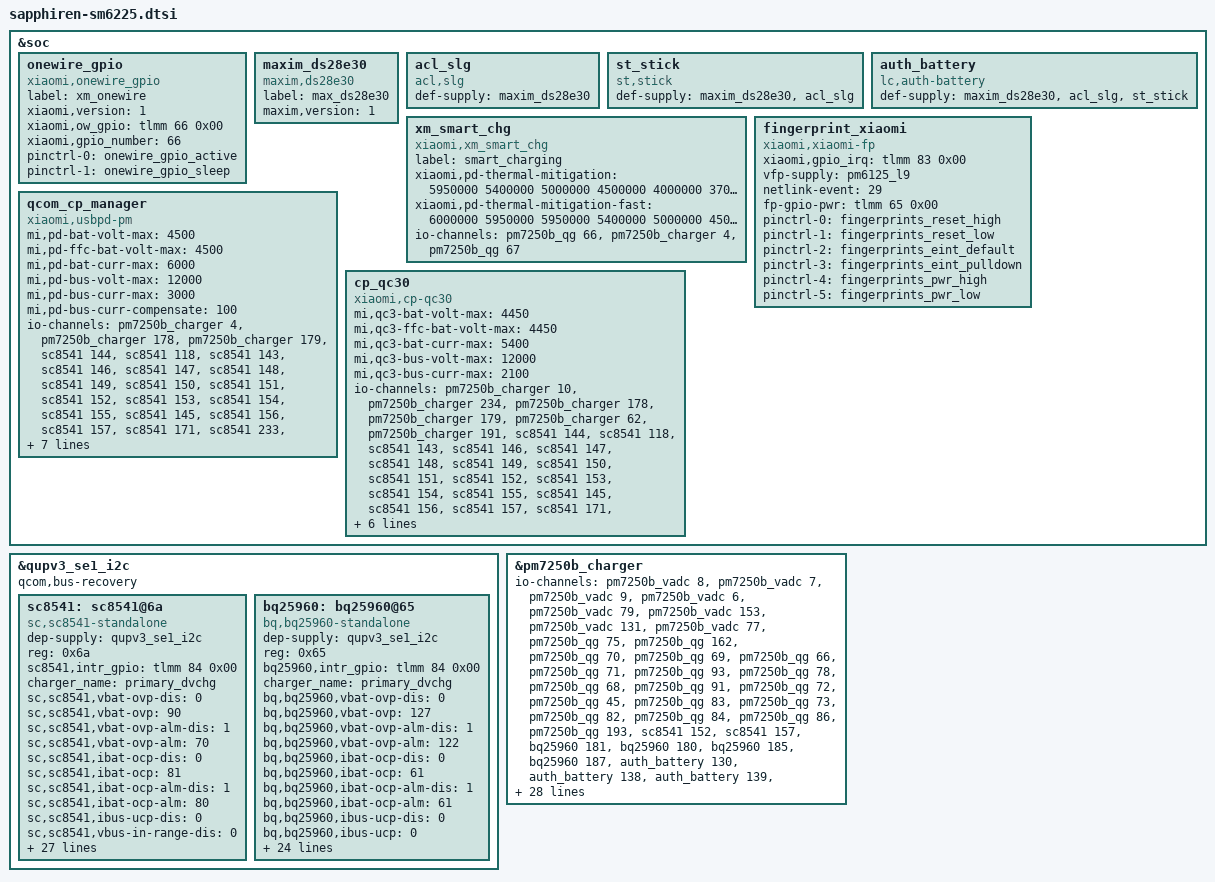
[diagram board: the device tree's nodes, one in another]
#include "sapphiren-pinctrl.dtsi"
#include "xiaomi-sm6225-common.dtsi"

&soc {
	onewire_gpio: onewire_gpio {
		compatible = "xiaomi,onewire_gpio";
		label = "xm_onewire";
		xiaomi,version = <1>;
		xiaomi,ow_gpio = <&tlmm 66 0x00>;
		xiaomi,gpio_number = <66>;
		pinctrl-names = "default", "sleep";
		pinctrl-0 = <&onewire_gpio_active>;
		pinctrl-1 = <&onewire_gpio_sleep>;
		status = "ok";
	};

	maxim_ds28e30: maxim_ds28e30 {
		status = "ok";
		#io-channel-cells = <1>;
		compatible = "maxim,ds28e30";
		label = "max_ds28e30";
		maxim,version = <1>;
	};

	acl_slg: acl_slg {
		compatible = "acl,slg";
		status = "okay";
		def-supply = <&maxim_ds28e30>;
	};

	st_stick: st_stick {
		compatible = "st,stick";
		status = "okay";
		def-supply = <&maxim_ds28e30 &acl_slg>;
	};

	auth_battery: auth_battery {
		compatible = "lc,auth-battery";
		status = "okay";
		#io-channel-cells = <1>;
		def-supply = <&maxim_ds28e30 &acl_slg &st_stick>;
	};

	xm_smart_chg {
		compatible = "xiaomi,xm_smart_chg";
		status = "ok";
		label = "smart_charging";
        xiaomi,pd-thermal-mitigation      = <5950000 5400000 5000000 4500000
                                            4000000 3700000 3500000 3000000
                                            2800000 2500000 2000000 1500000
                                            1000000 800000 500000 350000
                                            800000 800000>;

        xiaomi,pd-thermal-mitigation-fast = <6000000 5950000 5950000 5400000
                                            5000000 4500000 4000000 3700000
                                            2800000 2500000 2000000 1500000
                                            1000000 800000 500000 350000
                                            800000 800000>;
		io-channels = <&pm7250b_qg 66>,
		              <&pm7250b_charger 4>,
					  <&pm7250b_qg 67>;
		io-channel-names = "capacity", "pd_active", "capacity_raw";
	};

	fingerprint_xiaomi {
		status = "okay";
		compatible = "xiaomi,xiaomi-fp";
		xiaomi,gpio_irq = <&tlmm 83 0x00>;
		vfp-supply = <&pm6125_l9>;
		netlink-event = <29>;
		fp-gpio-pwr = <&tlmm 65 0x00>;
		pinctrl-names = "reset_high", "reset_low",
		                "eint_default", "eint_pulldown",
						"pwr_high", "pwr_low";
		pinctrl-0 = <&fingerprints_reset_high>;
		pinctrl-1 = <&fingerprints_reset_low>;
		pinctrl-2 = <&fingerprints_eint_default>;
		pinctrl-3 = <&fingerprints_eint_pulldown>;
		pinctrl-4 = <&fingerprints_pwr_high>;
		pinctrl-5 = <&fingerprints_pwr_low>;
	};

    qcom_cp_manager {
    	compatible = "xiaomi,usbpd-pm";
    	status = "ok";
    	mi,pd-bat-volt-max = <4500>;
    	mi,pd-ffc-bat-volt-max = <4500>;
    	mi,pd-bat-curr-max = <6000>;
    	mi,pd-bus-volt-max = <12000>;
    	mi,pd-bus-curr-max = <3000>;
    	mi,pd-bus-curr-compensate = <100>;
    	#io-channel-cells = <1>;
    	io-channels =
    		<&pm7250b_charger 4>,
    		<&pm7250b_charger 178>,
    		<&pm7250b_charger 179>,
    		<&sc8541 144>,
    		<&sc8541 118>,
    		<&sc8541 143>,
    		<&sc8541 146>,
    		<&sc8541 147>,
    		<&sc8541 148>,
    		<&sc8541 149>,
    		<&sc8541 150>,
    		<&sc8541 151>,
    		<&sc8541 152>,
    		<&sc8541 153>,
    		<&sc8541 154>,
    		<&sc8541 155>,
    		<&sc8541 145>,
    		<&sc8541 156>,
    		<&sc8541 157>,
    		<&sc8541 171>,
    		<&sc8541 233>,
    		<&pm7250b_charger 172>,
    		<&pm7250b_charger 173>,
    		<&bq25960 144>,
    		<&bq25960 118>,
    		<&bq25960 143>,
    		<&bq25960 146>,
    		<&bq25960 147>,
    		<&bq25960 148>,
    		<&bq25960 149>,
    		<&bq25960 150>,
    		<&bq25960 151>,
    		<&bq25960 152>,
    		<&bq25960 153>,
    		<&bq25960 154>,
    		<&bq25960 155>,
    		<&bq25960 145>,
    		<&bq25960 156>,
    		<&bq25960 233>;
    	io-channel-names =
    		"pd_active",
    		"cp_input_suspend",
    		"battery_charging_enabled",
    		"present",
    		"charging_enabled",
    		"status",
    		"sc_battery_present",
    		"sc_vbus_present",
    		"sc_battery_voltage",
    		"sc_battery_current",
    		"sc_battery_temperature",
    		"sc_bus_voltage",
    		"sc_bus_current",
    		"sc_bus_temperature",
    		"sc_die_temperature",
    		"sc_alarm_status",
    		"sc_fault_status",
    		"sc_vbus_error_status",
    		"sc_chip_vendor",
    		"sc_chip_id",
    		"sc_set_cp_workmode",
    		"apdo_volt",
    		"apdo_curr",
    		"bq_present",
    		"bq_charging_enabled",
    		"bq_status",
    		"bq_battery_present",
    		"bq_vbus_present",
    		"bq_battery_voltage",
    		"bq_battery_current",
    		"bq_battery_temperature",
    		"bq_bus_voltage",
    		"bq_bus_current",
    		"bq_bus_temperature",
    		"bq_die_temperature",
    		"bq_alarm_status",
    		"bq_fault_status",
    		"bq_vbus_error_status",
    		"bq_set_cp_workmode";
    };

    cp_qc30 {
    	compatible = "xiaomi,cp-qc30";
    	status = "ok";
    	mi,qc3-bat-volt-max = <4450>;
    	mi,qc3-ffc-bat-volt-max = <4450>;
    	mi,qc3-bat-curr-max = <5400>;
    	mi,qc3-bus-volt-max = <12000>;
    	mi,qc3-bus-curr-max = <2100>;
    	#io-channel-cells = <1>;
    	io-channels =
    		<&pm7250b_charger 10>,
    		<&pm7250b_charger 234>,
    		<&pm7250b_charger 178>,
    		<&pm7250b_charger 179>,
    		<&pm7250b_charger 62>,
    		<&pm7250b_charger 191>,
    		<&sc8541 144>,
    		<&sc8541 118>,
    		<&sc8541 143>,
    		<&sc8541 146>,
    		<&sc8541 147>,
    		<&sc8541 148>,
    		<&sc8541 149>,
    		<&sc8541 150>,
    		<&sc8541 151>,
    		<&sc8541 152>,
    		<&sc8541 153>,
    		<&sc8541 154>,
    		<&sc8541 155>,
    		<&sc8541 145>,
    		<&sc8541 156>,
    		<&sc8541 157>,
    		<&sc8541 171>,
    		<&sc8541 188>,
    		<&bq25960 144>,
    		<&bq25960 118>,
    		<&bq25960 143>,
    		<&bq25960 146>,
    		<&bq25960 147>,
    		<&bq25960 148>,
    		<&bq25960 149>,
    		<&bq25960 150>,
    		<&bq25960 151>,
    		<&bq25960 152>,
    		<&bq25960 153>,
    		<&bq25960 154>,
    		<&bq25960 155>,
    		<&bq25960 145>,
    		<&bq25960 156>,
    		<&bq25960 188>;
    	io-channel-names =
    		"real_type",
    		"hvdcp3_type",
    		"cp_input_suspend",
    		"battery_charging_enabled",
    		"battery_dp_dm",
    		"battery_charging_limited",
    		"present",
    		"charging_enabled",
    		"status",
    		"sc_battery_present",
    		"sc_vbus_present",
    		"sc_battery_voltage",
    		"sc_battery_current",
    		"sc_battery_temperature",
    		"sc_bus_voltage",
    		"sc_bus_current",
    		"sc_bus_temperature",
    		"sc_die_temperature",
    		"sc_alarm_status",
    		"sc_fault_status",
    		"sc_vbus_error_status",
    		"sc_chip_vendor",
    		"sc_chip_id",
    		"sc_set_bus_protection",
    		"bq_present",
    		"bq_charging_enabled",
    		"bq_status",
    		"bq_battery_present",
    		"bq_vbus_present",
    		"bq_battery_voltage",
    		"bq_battery_current",
    		"bq_battery_temperature",
    		"bq_bus_voltage",
    		"bq_bus_current",
    		"bq_bus_temperature",
    		"bq_die_temperature",
    		"bq_alarm_status",
    		"bq_fault_status",
    		"bq_vbus_error_status",
    		"bq_set_bus_protection";
    };
};

&qupv3_se1_i2c {
    status = "ok";
	qcom,bus-recovery;
	sc8541: sc8541@6a {
		compatible = "sc,sc8541-standalone";
		status = "ok";
		dep-supply = <&qupv3_se1_i2c>;
		#io-channel-cells = <1>;
		reg = <0x6a>;
		sc8541,intr_gpio = <&tlmm 84 0x00>;
		charger_name = "primary_dvchg";
		sc,sc8541,vbat-ovp-dis = <0>;
		sc,sc8541,vbat-ovp = <90>;
		sc,sc8541,vbat-ovp-alm-dis = <1>;
		sc,sc8541,vbat-ovp-alm = <70>;
		sc,sc8541,ibat-ocp-dis = <0>;
		sc,sc8541,ibat-ocp = <81>;
		sc,sc8541,ibat-ocp-alm-dis = <1>;
		sc,sc8541,ibat-ocp-alm = <80>;
		sc,sc8541,ibus-ucp-dis = <0>;
		sc,sc8541,vbus-in-range-dis = <0>;
		sc,sc8541,vbus-pd-en = <0>;
		sc,sc8541,vbus-ovp = <100>;
		sc,sc8541,vbus-ovp-alm-dis = <1>;
		sc,sc8541,vbus-ovp-alm = <80>;
		sc,sc8541,ibus-ocp-dis = <0>;
		sc,sc8541,ibus-ocp = <13>;
		sc,sc8541,tshut-dis = <1>;
		sc,sc8541,tsbus-flt-dis = <1>;
		sc,sc8541,tsbat-flt-dis = <1>;
		sc,sc8541,tdie-alm = <200>;
		sc,sc8541,tsbus-flt = <21>;
		sc,sc8541,tsbat-flt = <21>;
		sc,sc8541,vac1-ovp = <3>;
		sc,sc8541,vac2-ovp = <3>;
		sc,sc8541,vac1-pd-en = <0>;
		sc,sc8541,vac2-pd-en = <0>;
		sc,sc8541,fsw-set = <4>;
		sc,sc8541,wd-timeout = <0>;
		sc,sc8541,wd-timeout-dis = <1>;
		sc,sc8541,ibat-sns-r = <0>;
		sc,sc8541,ss-timeout = <7>;
		sc,sc8541,ibus-ucp-fall-dg = <1>;
		sc,sc8541,vout-ovp-dis = <0>;
		sc,sc8541,ms = <0>;
		sc,sc8541,vout-ovp = <3>;
		sc,sc8541,pmid2out-uvp = <7>;
		sc,sc8541,pmid2out-ovp = <7>;
	};

	bq25960: bq25960@65 {
		compatible = "bq,bq25960-standalone";
		#io-channel-cells = <1>;
		status = "ok";
		dep-supply = <&qupv3_se1_i2c>;
		reg = <0x65>;
		bq25960,intr_gpio = <&tlmm 84 0x00>;
		charger_name = "primary_dvchg";
		bq,bq25960,vbat-ovp-dis = <0>;
		bq,bq25960,vbat-ovp = <127>;
		bq,bq25960,vbat-ovp-alm-dis = <1>;
		bq,bq25960,vbat-ovp-alm = <122>;
		bq,bq25960,ibat-ocp-dis = <0>;
		bq,bq25960,ibat-ocp = <61>;
		bq,bq25960,ibat-ocp-alm-dis = <1>;
		bq,bq25960,ibat-ocp-alm = <61>;
		bq,bq25960,ibus-ucp-dis = <0>;
		bq,bq25960,ibus-ucp = <0>;
		bq,bq25960,chg-config-2 = <0>;
		bq,bq25960,vbus-pd-en = <0>;
		bq,bq25960,vbus-ovp = <100>;
		bq,bq25960,vbus-ovp-alm-dis = <0>;
		bq,bq25960,vbus-ovp-alm = <100>;
		bq,bq25960,ibus-ocp = <13>;
		bq,bq25960,tsbus-flt-dis = <1>;
		bq,bq25960,tsbat-flt-dis = <1>;
		bq,bq25960,tdie-alm = <200>;
		bq,bq25960,tsbus-flt = <21>;
		bq,bq25960,tsbat-flt = <21>;
		bq,bq25960,vac1-ovp = <3>;
		bq,bq25960,vac2-ovp = <3>;
		bq,bq25960,vac1-pd-en = <0>;
		bq,bq25960,vac2-pd-en = <0>;
		bq,bq25960,fsw-set = <4>;
		bq,bq25960,wd-timeout = <0>;
		bq,bq25960,wd-timeout-dis = <1>;
		bq,bq25960,ibat-sns-r = <0>;
		bq,bq25960,ss-timeout = <5>;
		bq,bq25960,ibus-ucp-fall-dg = <1>;
		bq,bq25960,vout-ovp-dis = <0>;
		bq,bq25960,ms = <0>;
		bq,bq25960,vout-ovp = <3>;
	};
};

&pm7250b_charger {
	status = "ok";
	#io-channel-cells = <1>;
	io-channels =
		<&pm7250b_vadc 8>,
		<&pm7250b_vadc 7>,
		<&pm7250b_vadc 9>,
		<&pm7250b_vadc 6>,
		<&pm7250b_vadc 79>,
		<&pm7250b_vadc 153>,
		<&pm7250b_vadc 131>,
		<&pm7250b_vadc 77>,
		<&pm7250b_qg 75>,
		<&pm7250b_qg 162>,
		<&pm7250b_qg 70>,
		<&pm7250b_qg 69>,
		<&pm7250b_qg 66>,
		<&pm7250b_qg 71>,
		<&pm7250b_qg 93>,
		<&pm7250b_qg 78>,
		<&pm7250b_qg 68>,
		<&pm7250b_qg 91>,
		<&pm7250b_qg 72>,
		<&pm7250b_qg 45>,
		<&pm7250b_qg 83>,
		<&pm7250b_qg 73>,
		<&pm7250b_qg 82>,
		<&pm7250b_qg 84>,
		<&pm7250b_qg 86>,
		<&pm7250b_qg 193>,
		<&sc8541 152>,
		<&sc8541 157>,
		<&bq25960 181>,
		<&bq25960 180>,
		<&bq25960 185>,
		<&bq25960 187>,
		<&auth_battery 130>,
		<&auth_battery 138>,
		<&auth_battery 139>,
		<&auth_battery 137>;
	io-channel-names =
		"usb_in_voltage",
		"usb_in_current",
		"chg_temp",
		"die_temp",
		"conn_temp",
		"sbux_res",
		"vph_voltage",
		"skin_temp",
		"resistance_id",
		"fastcharge_mode",
		"voltage_now",
		"temp",
		"capacity",
		"voltage_ocv",
		"voltage_avg",
		"debug_battery",
		"real_capacity",
		"cc_soc",
		"current_now",
		"voltage_max",
		"charge_full",
		"charge_counter",
		"cycle_count",
		"charge_full_design",
		"time_to_full_now",
		"ffc_chg_termination_current",
		"sc_bus_current",
		"sc_manufacturer",
		"bq_bus_current",
		"bq_manufacturer",
		"batt_full_current",
		"bq_set_acdrv",
		"auth_batt_id",
		"auth_authen_result",
		"auth_manufacturer",
		"auth_chip_ok";
	qcom,battery-data = <&mtp_batterydata>;
	qcom,sec-charger-config = <0>;
	qcom,auto-recharge-soc = <95>;
	qcom,auto-recharge-vbat-mv = <100>;
	qcom,step-charging-enable;
	qcom,sw-jeita-enable;
	qcom,distinguish-qc-class-ab;
	qcom,charger-temp-max = <800>;
	qcom,smb-temp-max = <800>;
	qcom,suspend-input-on-debug-batt;
	qcom,fcc-stepping-enable;
	qcom,fcc-step-delay-ms = <100>;
	qcom,fcc-step-size-ua = <100000>;
	qcom,smb-internal-pull-kohm = <0>;
	qcom,en-skin-therm-mitigation;
	qcom,hvdcp3-standalone-config;
	qcom,disable-suspend-on-collapse;
	qcom,chg-term-current-ma = <(-250)>;
	qcom,fcc-max-ua = <6000000>;
	qcom,fv-max-uv = <4500000>;
	mi,use_third_cp;
	mi,support-ffc;
	qcom,thermal-mitigation =
		<5950000 5400000 5000000 4500000
		 4000000 3700000 3500000 3000000
		 2800000 2500000 2000000 1500000
		 1000000  800000  500000  350000
		 800000  800000>;
	qcom,hvdcp2-max-icl-ua = <2000000>;
	qcom,hvdcp2-12v-max-icl-ua = <1500000>;
	dpdm-supply = <&usb2_phy0>;
};
